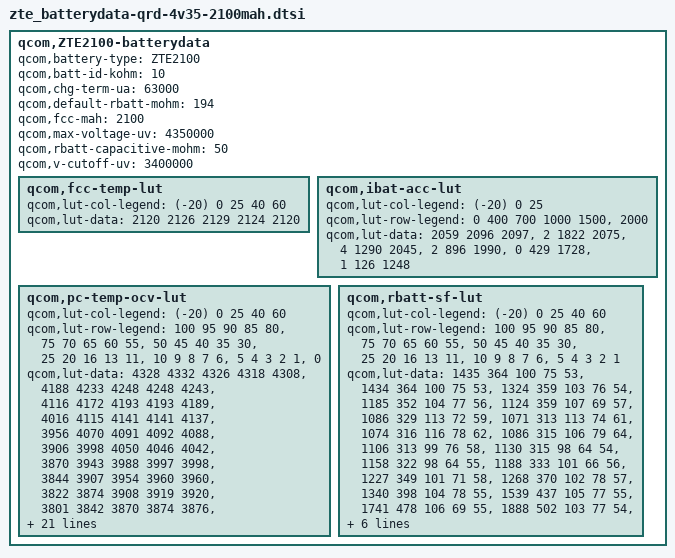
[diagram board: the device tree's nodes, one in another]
qcom,ZTE2100-batterydata {
	qcom,battery-type = "ZTE2100";
	qcom,batt-id-kohm = <10>;
	qcom,chg-term-ua = <63000>;
	qcom,default-rbatt-mohm = <194>;
	qcom,fcc-mah = <2100>;
	qcom,max-voltage-uv = <4350000>;
	qcom,rbatt-capacitive-mohm = <50>;
	qcom,v-cutoff-uv = <3400000>;

	qcom,fcc-temp-lut {
		qcom,lut-col-legend = <(-20) 0 25 40 60>;
		qcom,lut-data = <2120 2126 2129 2124 2120>;
	};

	qcom,ibat-acc-lut {
		qcom,lut-col-legend = <(-20) 0 25>;
		qcom,lut-row-legend = <0 400 700 1000 1500>,
					<2000>;
		qcom,lut-data = <2059 2096 2097>,
				<2 1822 2075>,
				<4 1290 2045>,
				<2 896 1990>,
				<0 429 1728>,
				<1 126 1248>;
	};

	qcom,pc-temp-ocv-lut {
		qcom,lut-col-legend = <(-20) 0 25 40 60>;
		qcom,lut-row-legend = <100 95 90 85 80>,
					<75 70 65 60 55>,
					<50 45 40 35 30>,
					<25 20 16 13 11>,
					<10 9 8 7 6>,
					<5 4 3 2 1>,
					<0>;
		qcom,lut-data = <4328 4332 4326 4318 4308>,
				<4188 4233 4248 4248 4243>,
				<4116 4172 4193 4193 4189>,
				<4016 4115 4141 4141 4137>,
				<3956 4070 4091 4092 4088>,
				<3906 3998 4050 4046 4042>,
				<3870 3943 3988 3997 3998>,
				<3844 3907 3954 3960 3960>,
				<3822 3874 3908 3919 3920>,
				<3801 3842 3870 3874 3876>,
				<3781 3815 3840 3843 3843>,
				<3762 3793 3817 3819 3818>,
				<3741 3776 3798 3799 3800>,
				<3720 3760 3780 3782 3782>,
				<3696 3744 3766 3766 3763>,
				<3670 3730 3752 3750 3740>,
				<3642 3718 3734 3732 3720>,
				<3616 3705 3712 3710 3697>,
				<3594 3693 3692 3686 3674>,
				<3576 3682 3687 3680 3669>,
				<3565 3676 3686 3679 3668>,
				<3553 3668 3684 3678 3667>,
				<3538 3659 3682 3676 3665>,
				<3521 3646 3678 3674 3663>,
				<3501 3630 3672 3668 3656>,
				<3476 3606 3652 3650 3633>,
				<3446 3576 3612 3612 3588>,
				<3405 3531 3554 3552 3528>,
				<3348 3464 3467 3470 3440>,
				<3261 3350 3326 3336 3299>,
				<3000 3000 3000 3000 3000>;
	};

	qcom,rbatt-sf-lut {
		qcom,lut-col-legend = <(-20) 0 25 40 60>;
		qcom,lut-row-legend = <100 95 90 85 80>,
					<75 70 65 60 55>,
					<50 45 40 35 30>,
					<25 20 16 13 11>,
					<10 9 8 7 6>,
					<5 4 3 2 1>;
		qcom,lut-data = <1435 364 100 75 53>,
				<1434 364 100 75 53>,
				<1324 359 103 76 54>,
				<1185 352 104 77 56>,
				<1124 359 107 69 57>,
				<1086 329 113 72 59>,
				<1071 313 113 74 61>,
				<1074 316 116 78 62>,
				<1086 315 106 79 64>,
				<1106 313 99 76 58>,
				<1130 315 98 64 54>,
				<1158 322 98 64 55>,
				<1188 333 101 66 56>,
				<1227 349 101 71 58>,
				<1268 370 102 78 57>,
				<1340 398 104 78 55>,
				<1539 437 105 77 55>,
				<1741 478 106 69 55>,
				<1888 502 103 77 54>,
				<1938 508 105 76 55>,
				<1988 504 107 78 56>,
				<2049 512 110 79 57>,
				<2214 527 113 81 58>,
				<2415 542 118 83 59>,
				<2656 561 123 84 60>,
				<2966 581 124 84 59>,
				<3393 606 123 81 57>,
				<4018 635 124 77 58>,
				<5166 674 129 79 59>,
				<8688 764 145 93 94>;
	};
};

